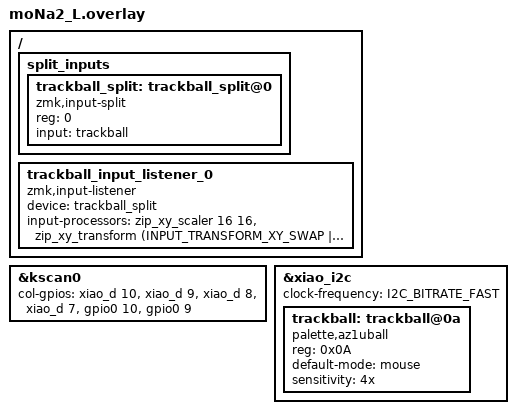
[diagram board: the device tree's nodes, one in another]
#include "moNa2.dtsi"
#include <input/processors.dtsi>
#include <dt-bindings/zmk/input_transform.h>

/ {
    split_inputs {
        #address-cells = <1>;
        #size-cells = <0>;

        trackball_split: trackball_split@0 {
            compatible = "zmk,input-split";
            reg = <0>;
            input = <&trackball>;  //       
        };
    };

    trackball_input_listener_0: trackball_input_listener_0 {
        compatible = "zmk,input-listener";
        status = "okay";
        device = <&trackball_split>;
        input-processors = <&zip_xy_scaler 16 16>,
                           <&zip_xy_transform (INPUT_TRANSFORM_XY_SWAP | INPUT_TRANSFORM_X_INVERT)>;
    };
};

&kscan0 {
    col-gpios = <&xiao_d 10 GPIO_ACTIVE_HIGH>,
                <&xiao_d 9 GPIO_ACTIVE_HIGH>,
                <&xiao_d 8 GPIO_ACTIVE_HIGH>,
                <&xiao_d 7 GPIO_ACTIVE_HIGH>,
                <&gpio0 10 GPIO_ACTIVE_HIGH>,
                <&gpio0 9 GPIO_ACTIVE_HIGH>;
};

&xiao_i2c {
    status = "okay";
    clock-frequency = <I2C_BITRATE_FAST>;
    trackball: trackball@0a {
        compatible = "palette,az1uball";
        reg = <0x0A>;
        status = "okay";
        default-mode = "mouse";
        sensitivity = "4x";
    };
};
